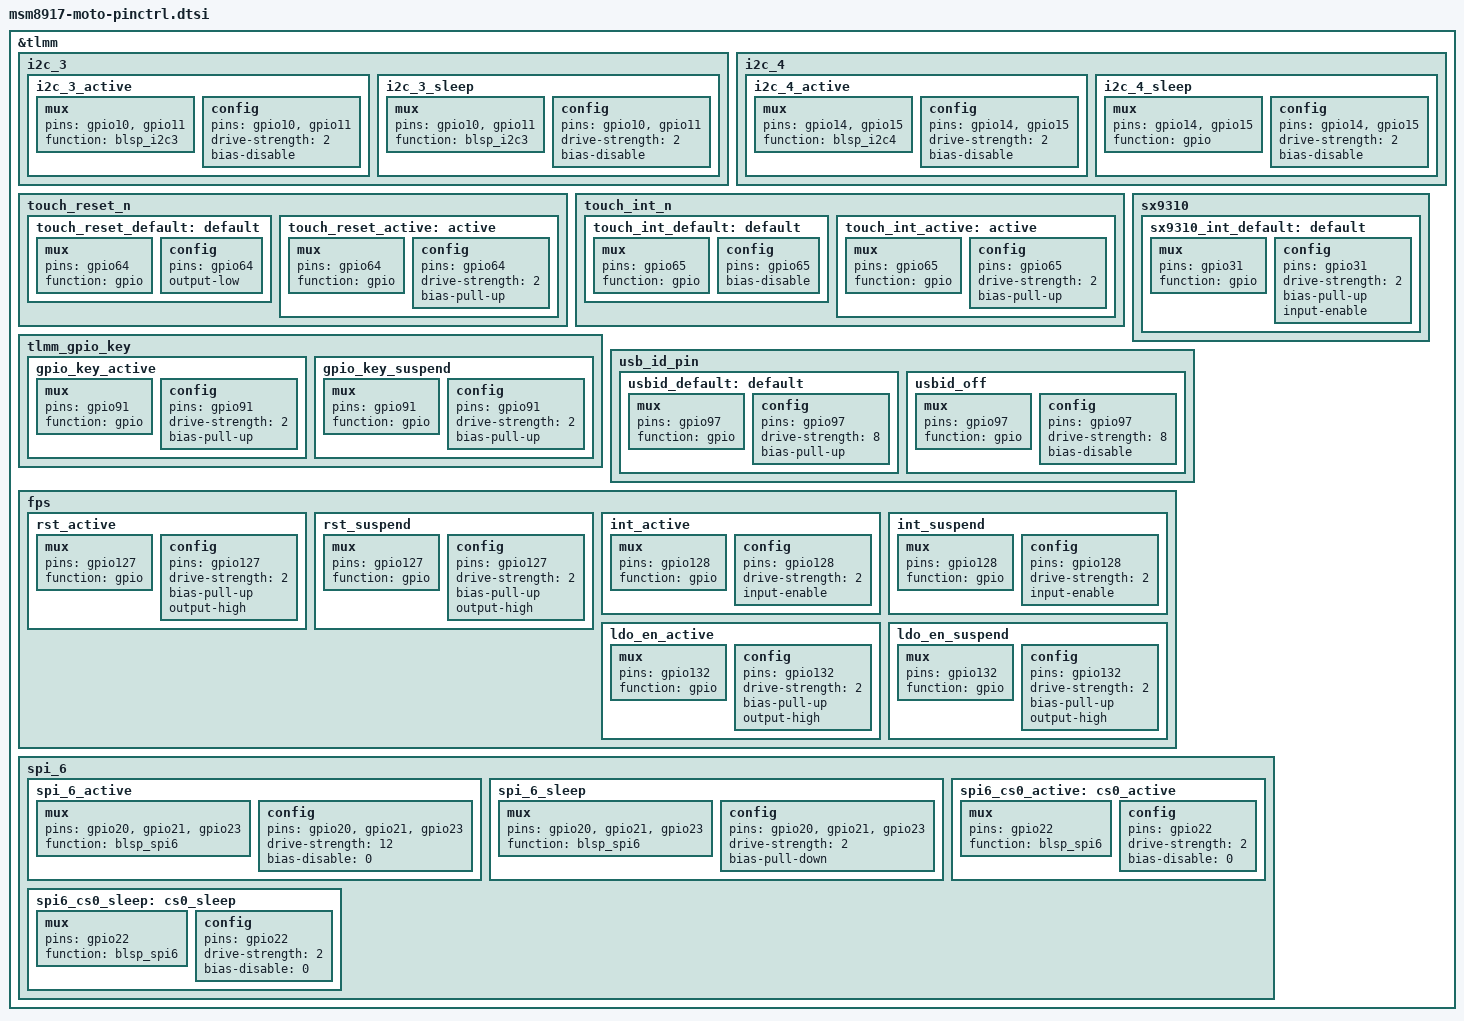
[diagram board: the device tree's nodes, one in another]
/* Copyright (c) 2016, Motorola Mobility Inc. All rights reserved.
 *
 * This program is free software; you can redistribute it and/or modify
 * it under the terms of the GNU General Public License version 2 and
 * only version 2 as published by the Free Software Foundation.
 *
 * This program is distributed in the hope that it will be useful,
 * but WITHOUT ANY WARRANTY; without even the implied warranty of
 * MERCHANTABILITY or FITNESS FOR A PARTICULAR PURPOSE.  See the
 * GNU General Public License for more details.
 */

&tlmm{
	i2c_3 {
		i2c_3_active: i2c_3_active {
			/* active state */
			mux {
				pins = "gpio10", "gpio11";
				function = "blsp_i2c3";
			};

			config {
				pins = "gpio10", "gpio11";
				drive-strength = <2>;
				bias-disable;
			};
		};

		i2c_3_sleep: i2c_3_sleep {
			/* suspended state */
			mux {
				pins = "gpio10", "gpio11";
				function = "blsp_i2c3";
			};

			config {
				pins = "gpio10", "gpio11";
				drive-strength = <2>;
				bias-disable;
			};
		};
	};

	i2c_4 {
		i2c_4_active: i2c_4_active {
			/* active state */
			mux {
				pins = "gpio14", "gpio15";
				function = "blsp_i2c4";
		};

		config {
				pins = "gpio14", "gpio15";
				drive-strength = <2>;
				bias-disable;
			};
		};

		i2c_4_sleep: i2c_4_sleep {
			/* suspended state */
			mux {
				pins = "gpio14", "gpio15";
				function = "gpio";
			};

			config {
				pins = "gpio14", "gpio15";
				drive-strength = <2>;
				bias-disable;
			};
		};
	};

	touch_reset_n {
		/*label = "touch-reset";*/

		touch_reset_default: default {
			mux {
				pins = "gpio64";
				function = "gpio";
			};

			config {
				pins = "gpio64";
				output-low;
			};
		};

		touch_reset_active: active {
			mux {
				pins = "gpio64";
				function = "gpio";
			};

			config {
				pins = "gpio64";
				drive-strength = <2>;   /* 2 mA */
				bias-pull-up; /* pull-up */
			};
		};
	};

	touch_int_n {
		/*label = "touch-int";*/

		touch_int_default: default {
			mux {
				pins = "gpio65";
				function = "gpio";
			};

			config {
				pins = "gpio65";
				bias-disable;
			};
		};

		touch_int_active: active {
			mux {
				pins = "gpio65";
				function = "gpio";
			};

			config {
				pins = "gpio65";
				drive-strength = <2>;
				bias-pull-up; /* pull-up */
			};
		};
	};

	sx9310 {
		sx9310_int_default: default {
			    mux {
				    pins = "gpio31";
				    function = "gpio";
			    };

			    config {
				    pins = "gpio31";
				    drive-strength = <2>;
				    bias-pull-up;
				    input-enable;
			    };
		    };
	};

	tlmm_gpio_key {
		gpio_key_active: gpio_key_active {
			mux {
				pins = "gpio91";
				function = "gpio";
			};

			config {
				pins = "gpio91";
				drive-strength = <2>;
				bias-pull-up;
			};
		};

		gpio_key_suspend: gpio_key_suspend {
			mux {
				pins = "gpio91";
				function = "gpio";
			};

			config {
				pins = "gpio91";
				drive-strength = <2>;
				bias-pull-up;
			};
		};
	};

	usb_id_pin {
		usbid_default: default {
			mux {
				pins = "gpio97";
				function = "gpio";
			};
			config {
				pins = "gpio97";
				drive-strength = <8>;
				bias-pull-up;
			};
		};
		usbid_off: usbid_off {
			mux {
				pins = "gpio97";
				function = "gpio";
			};
			config {
				pins = "gpio97";
				drive-strength = <8>;
				bias-disable;
			};
		};
	};

	fps: fps {
		rst_active: rst_active {
			/* RESET */
			mux {
				pins = "gpio127";
				function = "gpio";
			};

			config {
				pins = "gpio127";
				drive-strength = <2>; /* 2 MA */
				bias-pull-up; /* pull up */
				output-high;
			};
		};

		rst_suspend: rst_suspend{
			/* RESET */
			mux {
				pins = "gpio127";
				function = "gpio";
			};

			config {
				pins = "gpio127";
				drive-strength = <2>; /* 2 MA */
				bias-pull-up; /* pull up */
				output-high;
			};
		};

		int_active: int_active {
			/* INTERRUPT */
			mux {
				pins = "gpio128";
				function = "gpio";
			};

			config {
				pins = "gpio128";
				drive-strength = <2>; /* 2 MA */
				input-enable;
			};
		};

		int_suspend: int_suspend{
			/* INTERRUPT */
			mux {
				pins = "gpio128";
				function = "gpio";
			};

			config {
				pins = "gpio128";
				drive-strength = <2>; /* 2 MA */
				input-enable;
			};
		};

		ldo_en_active: ldo_en_active {
			/* LDO_EN */
			mux {
				pins = "gpio132";
				function = "gpio";
			};

			config {
				pins = "gpio132";
				drive-strength = <2>; /* 2 MA */
				bias-pull-up; /* pull up */
				output-high;
			};
		};

		ldo_en_suspend: ldo_en_suspend{
			/* LDO_EN */
			mux {
				pins = "gpio132";
				function = "gpio";
			};

			config {
				pins = "gpio132";
				drive-strength = <2>; /* 2 MA */
				bias-pull-up; /* pull up */
				output-high;
			};
		};

	};

	spi_6 {
		spi_6_active: spi_6_active {
			mux {
				/* MOSI, MISO, CLK */
				pins = "gpio20", "gpio21", "gpio23";
				function = "blsp_spi6";
			};

			config {
				pins = "gpio20", "gpio21", "gpio23";
				drive-strength = <12>; /* 12 MA */
				bias-disable = <0>; /* No PULL */
			};
		};

		spi_6_sleep: spi_6_sleep {
			mux {
				/* MOSI, MISO, CLK */
				pins = "gpio20", "gpio21", "gpio23";
				function = "blsp_spi6";
			};

			config {
				pins = "gpio20", "gpio21", "gpio23";
				drive-strength = <2>; /* 2 MA */
				bias-pull-down; /* PULL Down */
			};
		};

		spi6_cs0_active: cs0_active {
			mux {
				pins = "gpio22";
				function = "blsp_spi6";
			};

			config {
				pins = "gpio22";
				drive-strength = <2>;
				bias-disable = <0>;
			};
		};

		spi6_cs0_sleep: cs0_sleep {
			mux {
				pins = "gpio22";
				function = "blsp_spi6";
			};

			config {
				pins = "gpio22";
				drive-strength = <2>;
				bias-disable = <0>;
			};
		};
	};

};
